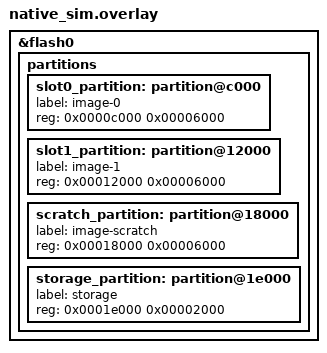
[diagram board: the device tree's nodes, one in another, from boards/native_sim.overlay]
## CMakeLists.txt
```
# Copyright (c) 2025 Nordic Semiconductor ASA
# SPDX-License-Identifier: Apache-2.0

cmake_minimum_required(VERSION 3.20.0)

find_package(Zephyr REQUIRED HINTS $ENV{ZEPHYR_BASE})
project(mcuboot_image_size_check_sysbuild_test)

test_sysbuild()

target_sources(app PRIVATE src/main.c)
```

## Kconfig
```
# Copyright (c) 2025 Nordic Semiconductor ASA
# SPDX-License-Identifier: Apache-2.0

config TEST_BLOAT_SIZE
	int "Padding array size in bytes to inflate the binary"
	default 0
	help
	  Size of a const padding array linked into .rodata.
	  Used to push the signed image close to or beyond the
	  slot size limit for testing the MCUboot image size check.

source "Kconfig.zephyr"
```

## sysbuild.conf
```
SB_CONFIG_BOOTLOADER_MCUBOOT=y
```

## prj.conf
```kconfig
CONFIG_BUILD_OUTPUT_BIN=y
```

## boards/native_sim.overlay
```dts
/*
 * Copyright (c) 2025 Nordic Semiconductor ASA
 * SPDX-License-Identifier: Apache-2.0
 *
 * Shrink the MCUboot image slots to 24 KB so the image size check can be
 * exercised with a small padding array.
 *
 * With erase-block-size = 4096 and swap-using-offset mode the estimated
 * footer is 2 * 4096 = 8192 bytes, leaving max image = 24576 - 8192 = 16384.
 */

/delete-node/ &slot0_partition;
/delete-node/ &slot1_partition;
/delete-node/ &scratch_partition;
/delete-node/ &storage_partition;

&flash0 {
	partitions {
		slot0_partition: partition@c000 {
			label = "image-0";
			reg = <0x0000c000 0x00006000>;
		};

		slot1_partition: partition@12000 {
			label = "image-1";
			reg = <0x00012000 0x00006000>;
		};

		scratch_partition: partition@18000 {
			label = "image-scratch";
			reg = <0x00018000 0x00006000>;
		};

		storage_partition: partition@1e000 {
			label = "storage";
			reg = <0x0001e000 0x00002000>;
		};
	};
};
```

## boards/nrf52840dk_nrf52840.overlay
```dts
/*
 * Copyright (c) 2025 Nordic Semiconductor ASA
 * SPDX-License-Identifier: Apache-2.0
 *
 * Shrink the MCUboot image slots to 48 KB so the image size check can be
 * exercised with a padding array.  The nrf52840dk base image is ~25 KB due
 * to HAL drivers, so 24 KB slots (as used for native_sim) are too small.
 *
 * With erase-block-size = 4096 and swap-using-offset mode the estimated
 * footer is 2 * 4096 = 8192 bytes, leaving max image = 49152 - 8192 = 40960.
 */

/delete-node/ &slot0_partition;
/delete-node/ &slot1_partition;
/delete-node/ &storage_partition;

&flash0 {
	partitions {
		slot0_partition: partition@c000 {
			label = "image-0";
			reg = <0x0000c000 0x0000c000>;
		};

		slot1_partition: partition@18000 {
			label = "image-1";
			reg = <0x00018000 0x0000c000>;
		};

		storage_partition: partition@24000 {
			label = "storage";
			reg = <0x00024000 0x00008000>;
		};
	};
};
```

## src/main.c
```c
/*
 * Copyright (c) 2025 Nordic Semiconductor ASA
 *
 * SPDX-License-Identifier: Apache-2.0
 */

#include <zephyr/kernel.h>

#if CONFIG_TEST_BLOAT_SIZE > 0
static const volatile uint8_t padding[CONFIG_TEST_BLOAT_SIZE] = {[0] = 0xAA};
#endif

int main(void)
{
#if CONFIG_TEST_BLOAT_SIZE > 0
	/* Reference the array so the linker cannot discard it. */
	printk("padding[0] = 0x%02x, size = %u\n", padding[0], CONFIG_TEST_BLOAT_SIZE);
#endif
	printk("MCUboot image size check sysbuild test\n");
	return 0;
}
```
